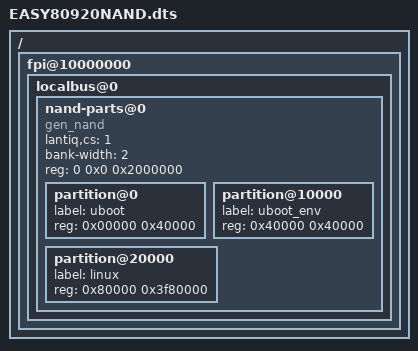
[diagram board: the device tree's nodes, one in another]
/dts-v1/;


/include/ "EASY80920.dtsi"

/ {
	fpi@10000000 {
		localbus@0 {
			ranges = <0 0 0x4000000 0x3ffffff>;
			nand-parts@0 {
				compatible = "gen_nand", "lantiq,nand-xway";
				lantiq,cs = <1>;
				bank-width = <2>;
				reg = <0 0x0 0x2000000>;
				#address-cells = <1>;
				#size-cells = <1>;

				partition@0 {
					label = "uboot";
					reg = <0x00000 0x40000>;
				};

				partition@10000 {
					label = "uboot_env";
					reg = <0x40000 0x40000>;
				};

				partition@20000 {
					label = "linux";
					reg = <0x80000 0x3f80000>;
				};
			};
		};
	};
};
